AUTOSAR XML (schema 00048)
package /ComponentTypes
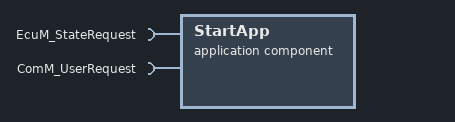
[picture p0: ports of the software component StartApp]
  application sw component type StartApp
    require port EcuM_StateRequest: required-com-specs=[GetStateWrapper, RequestRUN, RequestPOSTRUN, ReleaseRUN, ReleasePOSTRUN], required-interface=EcuM_StateRequest
    require port ComM_UserRequest: required-com-specs=[GetRequestedComMode, GetMaxComMode, GetCurrentComMode, RequestComMode], required-interface=ComM_UserRequest
    behavior StartApp_InternalBehavior: data-type-mapping=MotorDataTypeMappingSet
      init event StartApp_InitEvent: start-on-event=StartApp_Init
      4 x timing event:
        TMT_StartApp_Cyclic1ms: start-on-event=StartApp_Cyclic1ms, period=0.001
        TMT_StartApp_Cyclic500ms: start-on-event=StartApp_Cyclic250ms, period=0.25
        TMT_StartApp_Cyclic10ms: start-on-event=StartApp_Cyclic10ms, period=0.01
        TMT_StartApp_Cyclic1000ms: start-on-event=StartApp_Cyclic1000ms, period=1
      5 x runnable:
        StartApp_Cyclic250ms
        StartApp_Cyclic1ms
        StartApp_Init
          sync call AC_EcuM_StateRequest_RequestRUN: operation=EcuM_StateRequest.RequestRUN
          sync call SC_ComM_UserRequest_RequestComMode: operation=ComM_UserRequest.RequestComMode
        StartApp_Cyclic10ms
        StartApp_Cyclic1000ms
      swc service dependency EcuMUserNeed: assigned-ports=[EcuM_StateRequest, {port-prototype=EcuM_StateRequest, role=EcuM_StateRequest}]
        service-needs:
          ecu state mgr user needs EcuMUserNeed
  swc implementation StartApp_Implementation: behavior=StartApp_InternalBehavior
